# ESP32S31_RADIO register map
Vendor: Espressif; Series: ESP32-S31; File version: 3.52
Registers are 32-bit, read-write, no defined reset value unless marked. A register's access mark holds for its fields unless they carry their own. Offsets are from the block's base; [hi:lo] are bit positions; {n}, {i} and the like mark numbered series.

## WIFI_MAC_TXRX_SUFFIX — Eight Wi-Fi-owned direct fresh-read RMW edges after the three external HE callbacks in complete mac_txrx_init. The ninth edge reaches the independently shared physical word at 0x20104C24 and is modeled by SHARED_RADIO_INIT_CONTROL.
Base 0x20104308
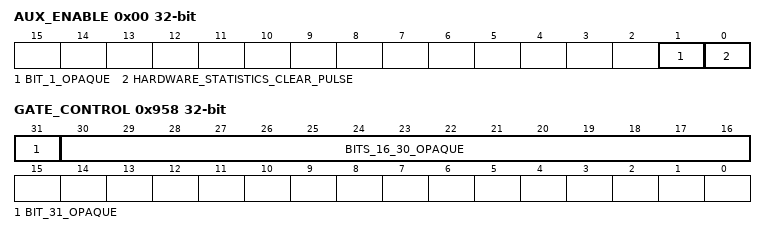
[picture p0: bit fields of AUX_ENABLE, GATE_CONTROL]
0x00 AUX_ENABLE — Project-assigned name. The TX/RX init suffix sets bit 1. Complete dbg_clr_hw_count reaches esp_test_clr_hw_statistics, which independently pulses bit 0 high then low while the matching core statistics-clear arm is asserted.
  [1] BIT_1_OPAQUE — Opaque: meaning not established.
  [0] HARDWARE_STATISTICS_CLEAR_PULSE — Project-assigned name. Set and then cleared by complete esp_test_clr_hw_statistics.
0x918 DEFAULT_IMAGE_A — Project-assigned name. Complete suffix replaces the low twelve bits with 0x0f0.
  [11:0] BITS_0_11_OPAQUE — Opaque: meaning not established.
0x958 GATE_CONTROL — Project-assigned name. Complete suffix sets bits 30:16 together, then sets bit 31 through a separate fresh-read edge.
  [31] BIT_31_OPAQUE — Opaque: meaning not established.
  [30:16] BITS_16_30_OPAQUE — Opaque: meaning not established.
0x9A0 FIELD_CONTROL — Project-assigned name. Complete suffix replaces bits 7:4 with four.
  [7:4] BITS_4_7_OPAQUE — Opaque: meaning not established.

## SHARED_RADIO_INIT_CONTROL — One physical radio word independently reached by Wi-Fi MAC initialization and Bluetooth receive setup. The owner is protocol-neutral because the two consumers update disjoint fields through fresh-read RMW operations; the name records the observed setup context without assigning an undocumented electrical meaning.
Base 0x20104C24
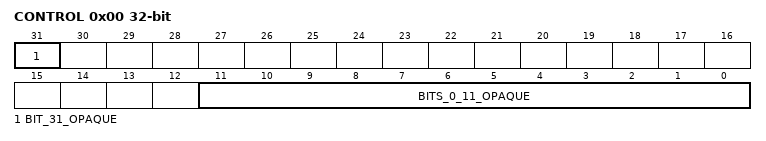
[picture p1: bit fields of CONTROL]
0x00 CONTROL — Project-assigned name. Complete mac_txrx_init replaces the low twelve bits with 0x0F0. Complete bt_bb_rx_set independently clears bit 31. Bits 30:12 remain unnamed.
  [31] BIT_31_OPAQUE — Opaque: meaning not established. Complete bt_bb_rx_set clears this bit through a fresh-read RMW while preserving bits 30:0. Its hardware meaning remains unknown.
  [11:0] BITS_0_11_OPAQUE — Opaque: meaning not established. Complete mac_txrx_init replaces this field with the finite image 0x0F0 while preserving bits 31:12.

## WIFI_MAC_RX_CSI_CONTROL — Multifunction receive/CSI word. Complete mac_last_rxbuf_init sets bit 27; complete hal_init later replaces its low and second bytes through separate RMWs.
Base 0x20104098
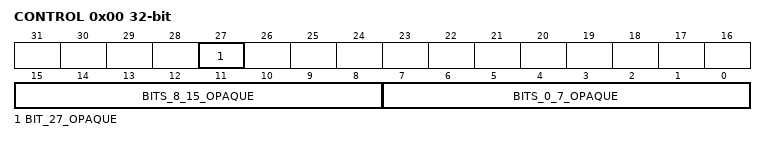
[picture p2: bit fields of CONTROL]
0x00 CONTROL — Project-assigned name. Complete mac_last_rxbuf_init sets bit 27 after publishing all six table entries and both control groups. Complete hal_init later replaces byte zero with one, then byte one with one through a second fresh-read edge.
  [27] BIT_27_OPAQUE — Opaque: meaning not established. Final set edge of mac_last_rxbuf_init; its narrower interaction with CSI is unknown.
  [15:8] BITS_8_15_OPAQUE — Opaque: meaning not established. Complete hal_init replaces bits 15:8 with one through a separate RMW.
    on write: 1=INITIALIZED
  [7:0] BITS_0_7_OPAQUE — Opaque: meaning not established. Complete hal_init replaces bits 7:0 with one.
    on write: 1=INITIALIZED

## WIFI_MAC_LAST_RX_BUFFER — Six three-word last-RX-buffer entries and their shared two-edge enable control, recovered from the complete mac_last_rxbuf_init leaf.
Base 0x20104120
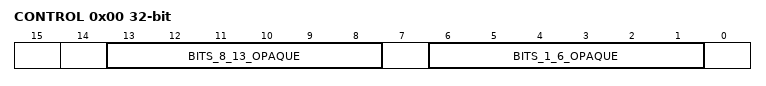
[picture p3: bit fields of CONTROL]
0x00 CONTROL — Project-assigned name. Complete leaf sets bits 13:8 first, then sets bits 6:1 through a second fresh-read RMW.
  [13:8] BITS_8_13_OPAQUE — Opaque: meaning not established. All six bits are set by the first control RMW.
  [6:1] BITS_1_6_OPAQUE — Opaque: meaning not established. All six bits are set by the second control RMW.
{0x4+4i} ENTRY_CONTROL{i} (i=0..5) wo — Project-assigned name. First full-word image for each of six entries.
  [31:0] BITS_0_31_OPAQUE — Opaque: meaning not established.
{0x20+4i} ENTRY_PARAMETER_A{i} (i=0..5) wo — Project-assigned name. Second full-word image for each of six entries.
  [31:0] BITS_0_31_OPAQUE — Opaque: meaning not established.
{0x3C+4i} ENTRY_PARAMETER_B{i} (i=0..5) wo — Project-assigned name. Third full-word image for each of six entries.
  [31:0] BITS_0_31_OPAQUE — Opaque: meaning not established.
